# ATSAML11E14A register map
Vendor: Microchip Technology; Series: SAML11; File version: 0
CPU: CM23 r0p0, little endian, MPU, no FPU, 2 interrupt priority bits, 45 interrupts
Registers are 32-bit, read-write, reset 0x0 unless marked. A register's access mark holds for its fields unless they carry their own. Offsets are from the block's base; [hi:lo] are bit positions; {n}, {i} and the like mark numbered series; 'fields as' and 'values as' point back to an identical list.

## OSCCTRL — Oscillators Control
Base 0x40001000
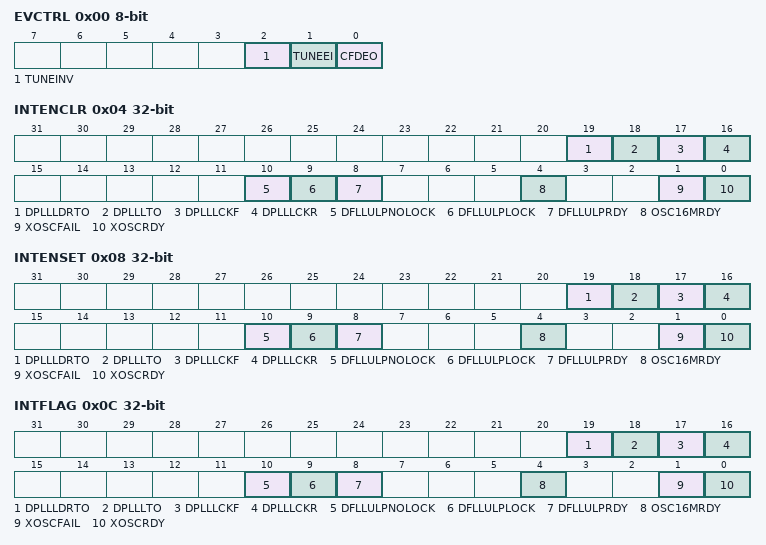
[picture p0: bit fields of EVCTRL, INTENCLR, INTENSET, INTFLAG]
0x00 EVCTRL 8-bit — Event Control
  [2] TUNEINV — Tune Event Input Invert
  [1] TUNEEI — Tune Event Input Enable
  [0] CFDEO — Clock Failure Detector Event Output Enable
0x04 INTENCLR write-1-clears — Interrupt Enable Clear
  [19] DPLLLDRTO — DPLL Loop Divider Ratio Update Complete Interrupt Enable
  [18] DPLLLTO — DPLL Lock Timeout Interrupt Enable
  [17] DPLLLCKF — DPLL Lock Fall Interrupt Enable
  [16] DPLLLCKR — DPLL Lock Rise Interrupt Enable
  [10] DFLLULPNOLOCK — DFLLULP No Lock Interrupt Enable
  [9] DFLLULPLOCK — DFLLULP Lock Interrupt Enable
  [8] DFLLULPRDY — DFLLULP Ready interrupt Enable
  [4] OSC16MRDY — OSC16M Ready Interrupt Enable
  [1] XOSCFAIL — XOSC Clock Failure Detector Interrupt Enable
  [0] XOSCRDY — XOSC Ready Interrupt Enable
0x08 INTENSET write-1-sets — Interrupt Enable Set
  fields as INTENCLR
0x0C INTFLAG write-1-clears — Interrupt Flag Status and Clear
  [19] DPLLLDRTO — DPLL Loop Divider Ratio Update Complete
  [18] DPLLLTO — DPLL Lock Timeout
  [17] DPLLLCKF — DPLL Lock Fall
  [16] DPLLLCKR — DPLL Lock Rise
  [10] DFLLULPNOLOCK
  [9] DFLLULPLOCK
  [8] DFLLULPRDY — DFLLULP Ready
  [4] OSC16MRDY — OSC16M Ready
  [1] XOSCFAIL — XOSC Clock Failure Detector
  [0] XOSCRDY — XOSC Ready
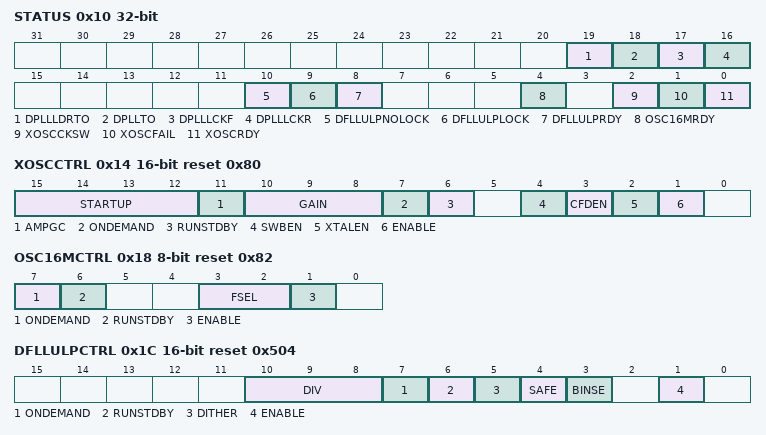
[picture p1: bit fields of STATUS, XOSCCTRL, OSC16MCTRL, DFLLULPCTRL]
0x10 STATUS ro
  [19] DPLLLDRTO — DPLL Loop Divider Ratio Update Complete
  [18] DPLLTO — DPLL Lock Timeout
  [17] DPLLLCKF — DPLL Lock Fall
  [16] DPLLLCKR — DPLL Lock Rise
  [10] DFLLULPNOLOCK
  [9] DFLLULPLOCK
  [8] DFLLULPRDY — DFLLULP Ready
  [4] OSC16MRDY — OSC16M Ready
  [2] XOSCCKSW — XOSC Clock Switch
  [1] XOSCFAIL — XOSC Clock Failure Detector
  [0] XOSCRDY — XOSC Ready
0x14 XOSCCTRL 16-bit reset 0x80 — External Multipurpose Crystal Oscillator (XOSC) Control
  [15:12] STARTUP — Start-Up Time
    0=CYCLE1 (31 us); 1=CYCLE2 (61 us); 2=CYCLE4 (122 us); 3=CYCLE8 (244 us); 4=CYCLE16 (488 us); 5=CYCLE32 (977 us); 6=CYCLE64 (1953 us); 7=CYCLE128 (3906 us); 8=CYCLE256 (7813 us); 9=CYCLE512 (15625 us); 10=CYCLE1024 (31250 us); 11=CYCLE2048 (62500 us); 12=CYCLE4096 (125000 us); 13=CYCLE8192 (250000 us); 14=CYCLE16384 (500000 us); 15=CYCLE32768 (1000000 us)
  [11] AMPGC — Automatic Amplitude Gain Control
  [10:8] GAIN — Oscillator Gain
    0=2 MHz; 1=4 MHz; 2=8 MHz; 3=16 MHz; 4=30 MHz
  [7] ONDEMAND — On Demand Control
  [6] RUNSTDBY — Run in Standby
  [4] SWBEN — Xosc Clock Switch Enable
  [3] CFDEN — Clock Failure Detector Enable
  [2] XTALEN — Crystal Oscillator Enable
  [1] ENABLE — Oscillator Enable
0x16 CFDPRESC 8-bit — Clock Failure Detector Prescaler
  [2:0] CFDPRESC
    0=DIV1 (OSC16M/1); 1=DIV2 (OSC16M/2); 2=DIV4 (OSC16M/4); 3=DIV8 (OSC16M/8); 4=DIV16 (OSC16M/16); 5=DIV32 (OSC16M/32); 6=DIV64 (OSC16M/64); 7=DIV128 (OSC16M/128)
0x18 OSC16MCTRL 8-bit reset 0x82 — 16MHz Internal Oscillator (OSC16M) Control
  [7] ONDEMAND — On Demand Control
  [6] RUNSTDBY — Run in Standby
  [3:2] FSEL — Oscillator Frequency Selection
    0=4MHz; 1=8MHz; 2=12MHz; 3=16MHz
  [1] ENABLE — Oscillator Enable
0x1C DFLLULPCTRL 16-bit reset 0x504 — DFLLULP Control
  [10:8] DIV — Division Factor
    0=Frequency Divided by 1; 1=Frequency Divided by 2; 2=Frequency Divided by 4; 3=Frequency Divided by 8; 4=Frequency Divided by 16; 5=Frequency Divided by 32
  [7] ONDEMAND
  [6] RUNSTDBY — Run in Standby
  [5] DITHER — Tuner Dither Mode
  [4] SAFE — Tuner Safe Mode
  [3] BINSE — Binary Search Enable
  [1] ENABLE
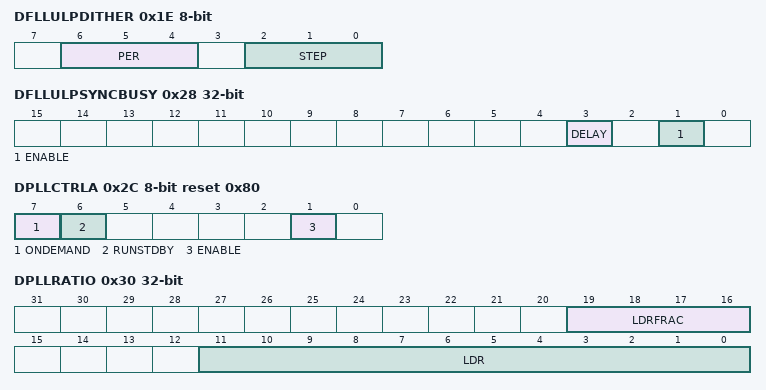
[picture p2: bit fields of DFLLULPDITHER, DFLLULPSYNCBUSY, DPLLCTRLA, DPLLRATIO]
0x1E DFLLULPDITHER 8-bit — DFLLULP Dither Control
  [6:4] PER — Dither Period
    0=Dither Over 1 Reference Clock Period; 1=Dither Over 2 Reference Clock Period; 2=Dither Over 4 Reference Clock Period; 3=Dither Over 8 Reference Clock Period; 4=Dither Over 16 Reference Clock Period; 5=Dither Over 32 Reference Clock Period
  [2:0] STEP — Dither Step
    0=Dither Step = 1; 1=Dither Step = 2; 2=Dither Step = 4; 3=Dither Step = 8
0x1F DFLLULPRREQ 8-bit — DFLLULP Read Request
  [7] RREQ — Read Request
0x20 DFLLULPDLY reset 0x80 — DFLLULP Delay Value
  [7:0] DELAY — Delay Value
0x24 DFLLULPRATIO — DFLLULP Target Ratio
  [10:0] RATIO — Target Tuner Ratio
0x28 DFLLULPSYNCBUSY ro — DFLLULP Synchronization Busy
  [3] DELAY — Delay Register Synchronization Busy
  [1] ENABLE — Enable Bit Synchronization Busy
0x2C DPLLCTRLA 8-bit reset 0x80 — DPLL Control A
  [7] ONDEMAND — On Demand Clock Activation
  [6] RUNSTDBY — Run in Standby
  [1] ENABLE — DPLL Enable
0x30 DPLLRATIO — DPLL Ratio Control
  [19:16] LDRFRAC — Loop Divider Ratio Fractional Part
  [11:0] LDR — Loop Divider Ratio
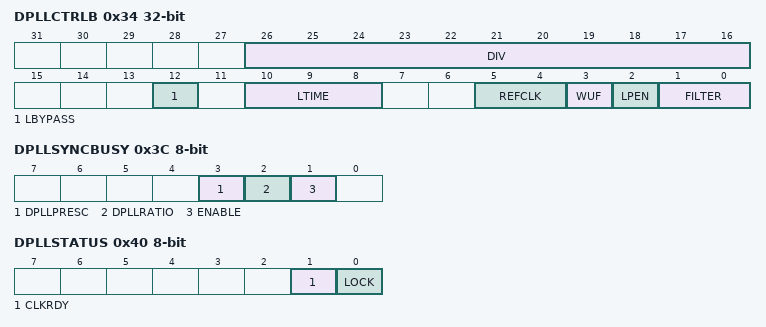
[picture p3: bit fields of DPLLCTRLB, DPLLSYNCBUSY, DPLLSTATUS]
0x34 DPLLCTRLB — DPLL Control B
  [26:16] DIV — Clock Divider
  [12] LBYPASS — Lock Bypass
  [10:8] LTIME — Lock Time
    0=Default (No time-out. Automatic lock); {v}={v+4}MS (Time-out if no lock within {v+4} ms) (v=4..7)
  [5:4] REFCLK — Reference Clock Selection
    0=XOSC32K (XOSC32K Clock Reference); 1=XOSC (XOSC Clock Reference); 2=GCLK (GCLK Clock Reference)
  [3] WUF — Wake Up Fast
  [2] LPEN — Low-Power Enable
  [1:0] FILTER — Proportional Integral Filter Selection
    0=Default Filter Mode; 1=LBFILT (Low Bandwidth Filter); 2=HBFILT (High Bandwidth Filter); 3=HDFILT (High Damping Filter)
0x38 DPLLPRESC 8-bit — DPLL Prescaler
  [1:0] PRESC — Output Clock Prescaler
    0=DIV1 (DPLL output is divided by 1); 1=DIV2 (DPLL output is divided by 2); 2=DIV4 (DPLL output is divided by 4)
0x3C DPLLSYNCBUSY 8-bit ro — DPLL Synchronization Busy
  [3] DPLLPRESC — DPLL Prescaler Synchronization Status
  [2] DPLLRATIO — DPLL Loop Divider Ratio Synchronization Status
  [1] ENABLE — DPLL Enable Synchronization Status
0x40 DPLLSTATUS 8-bit ro
  [1] CLKRDY — DPLL Clock Ready
  [0] LOCK — DPLL Lock

## Notices in the file
Copyright (c) 2026 Microchip Technology Inc.
SPDX-License-Identifier: Apache-2.0
Licensed under the Apache License, Version 2.0 (the "License");
you may not use this file except in compliance with the License.
You may obtain a copy of the License at
http://www.apache.org/licenses/LICENSE-2.0
Unless required by applicable law or agreed to in writing, software
distributed under the License is distributed on an "AS IS" BASIS,
WITHOUT WARRANTIES OR CONDITIONS OF ANY KIND, either express or implied.
See the License for the specific language governing permissions and
limitations under the License.
